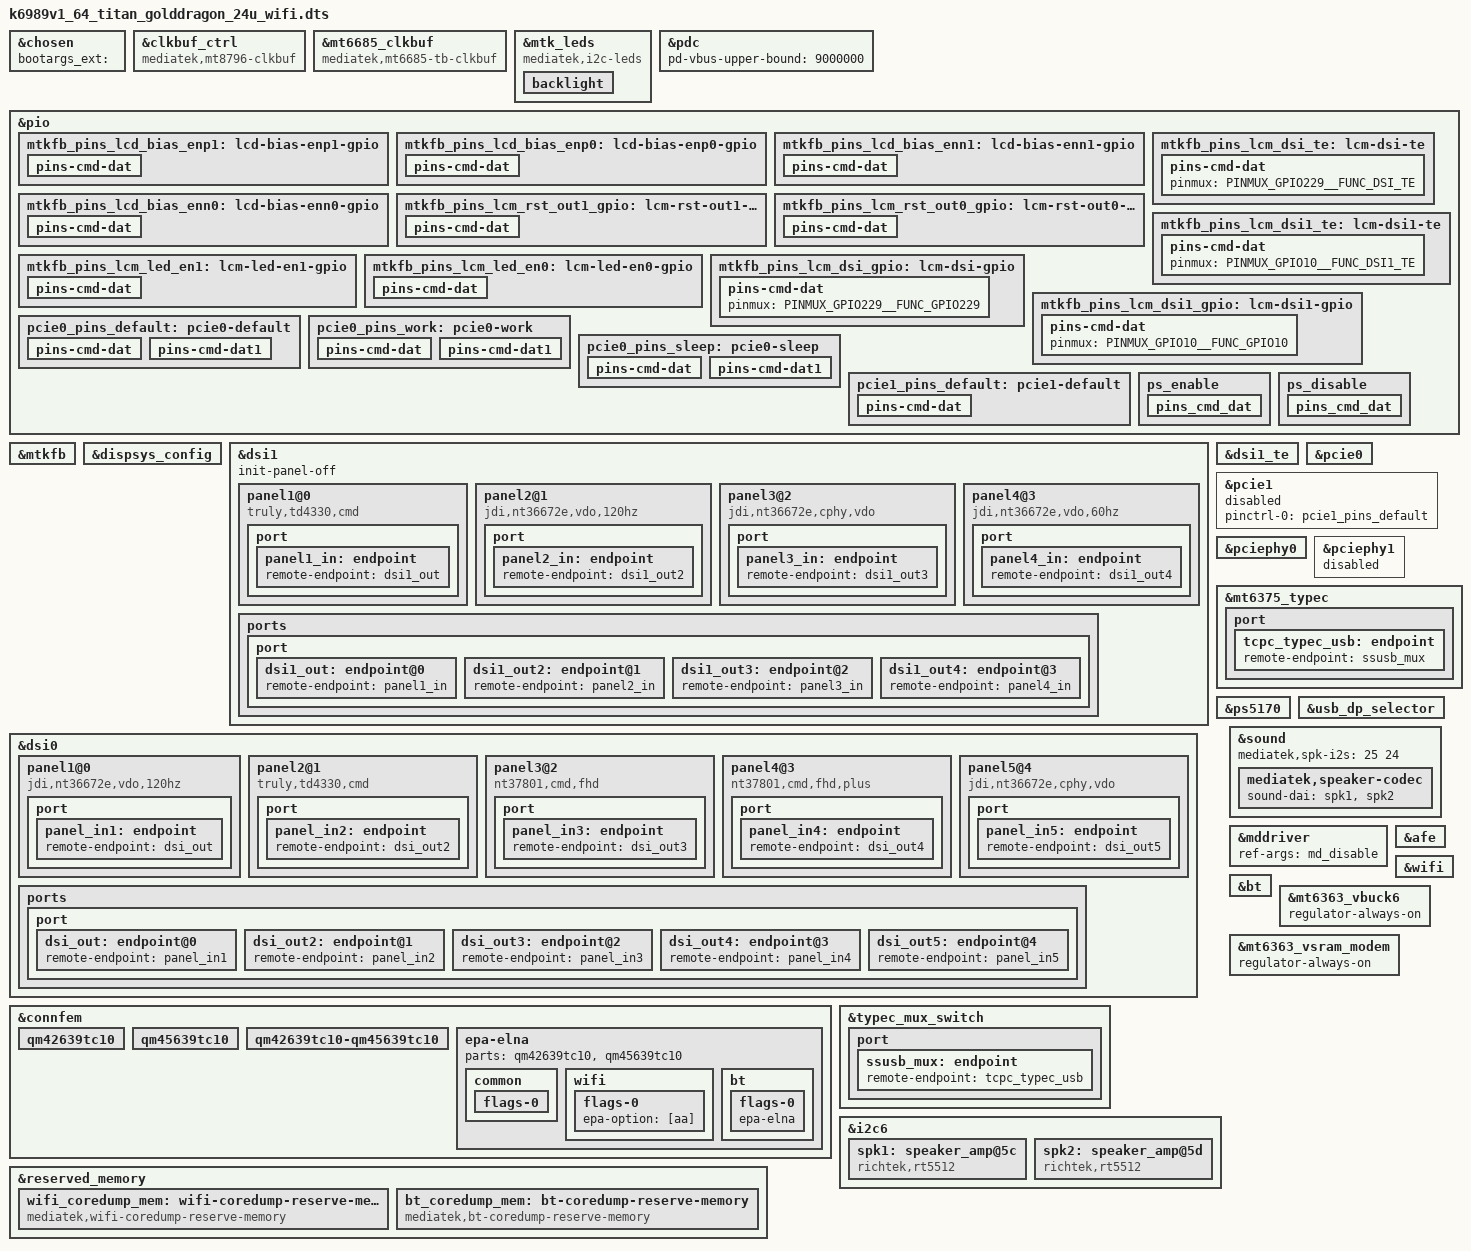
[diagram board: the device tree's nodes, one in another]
// SPDX-License-Identifier: (GPL-2.0 OR MIT)
/*
 * Copyright (C) 2022 MediaTek Inc.
 */
/dts-v1/;
/plugin/;
#include <dt-bindings/interrupt-controller/arm-gic.h>
#include <dt-bindings/interrupt-controller/irq.h>
#include <dt-bindings/pinctrl/mt6989-pinfunc.h>
#include <dt-bindings/phy/phy.h>

&chosen {
bootargs_ext = "";
};

&clkbuf_ctrl {
	compatible = "mediatek,mt8796-clkbuf";
};

&mt6685_clkbuf {
	compatible = "mediatek,mt6685-tb-clkbuf";
};

&mtk_leds {
	compatible = "mediatek,i2c-leds";

	backlight {
		led-mode = <6>;
		gate-enable = <1>;
		pwm-config = <0 1 0 0 0>;
	};
};

&pdc {
	pd-vbus-upper-bound = <9000000>;
};

&pio {
	mtkfb_pins_lcd_bias_enp1: lcd-bias-enp1-gpio {
		pins-cmd-dat {
			pinmux = <PINMUX_GPIO222__FUNC_GPIO222>;
			slew-rate = <1>;
			output-high;
		};
	};

	mtkfb_pins_lcd_bias_enp0: lcd-bias-enp0-gpio {
		pins-cmd-dat {
			pinmux = <PINMUX_GPIO222__FUNC_GPIO222>;
			slew-rate = <1>;
			output-low;
		};
	};

	mtkfb_pins_lcd_bias_enn1: lcd-bias-enn1-gpio {
		pins-cmd-dat {
			pinmux = <PINMUX_GPIO222__FUNC_GPIO222>;
			slew-rate = <1>;
			output-high;
		};
	};

	mtkfb_pins_lcd_bias_enn0: lcd-bias-enn0-gpio {
		pins-cmd-dat {
			pinmux = <PINMUX_GPIO222__FUNC_GPIO222>;
			slew-rate = <1>;
			output-low;
		};
	};

	mtkfb_pins_lcm_rst_out1_gpio: lcm-rst-out1-gpio {
		pins-cmd-dat {
			pinmux = <PINMUX_GPIO9__FUNC_GPIO9>;
			slew-rate = <1>;
			output-high;
		};
	};

	mtkfb_pins_lcm_rst_out0_gpio: lcm-rst-out0-gpio {
		pins-cmd-dat {
			pinmux = <PINMUX_GPIO230__FUNC_GPIO230>;
			slew-rate = <1>;
			output-low;
		};
	};

	mtkfb_pins_lcm_dsi_te: lcm-dsi-te {
		pins-cmd-dat {
			pinmux = <PINMUX_GPIO229__FUNC_DSI_TE>;
		};
	};

	mtkfb_pins_lcm_led_en1: lcm-led-en1-gpio {
		pins-cmd-dat {
			pinmux = <PINMUX_GPIO215__FUNC_GPIO215>;
			slew-rate = <1>;
			output-high;
		};
	};

	mtkfb_pins_lcm_led_en0: lcm-led-en0-gpio {
		pins-cmd-dat {
			pinmux = <PINMUX_GPIO215__FUNC_GPIO215>;
			slew-rate = <1>;
			output-low;
		};
	};

	mtkfb_pins_lcm_dsi1_te: lcm-dsi1-te {
		pins-cmd-dat {
			pinmux = <PINMUX_GPIO10__FUNC_DSI1_TE>;
		};
	};

	mtkfb_pins_lcm_dsi_gpio: lcm-dsi-gpio {
		pins-cmd-dat {
			pinmux = <PINMUX_GPIO229__FUNC_GPIO229>;
		};
	};

	mtkfb_pins_lcm_dsi1_gpio: lcm-dsi1-gpio {
		pins-cmd-dat {
			pinmux = <PINMUX_GPIO10__FUNC_GPIO10>;
		};
	};
};

&mtkfb {
	pinctrl-names = "lcd_bias_enp1_gpio", "lcd_bias_enp0_gpio",
		"lcd_bias_enn1_gpio", "lcd_bias_enn0_gpio",
		"lcm_rst_out1_gpio", "lcm_rst_out0_gpio",
		"mode_te_te", "lcm_led_en1_gpio", "lcm_led_en0_gpio",
		"mode_te_te1";
	pinctrl-0 = <&mtkfb_pins_lcd_bias_enp1>;
	pinctrl-1 = <&mtkfb_pins_lcd_bias_enp0>;
	pinctrl-2 = <&mtkfb_pins_lcd_bias_enn1>;
	pinctrl-3 = <&mtkfb_pins_lcd_bias_enn0>;
	pinctrl-4 = <&mtkfb_pins_lcm_rst_out1_gpio>;
	pinctrl-5 = <&mtkfb_pins_lcm_rst_out0_gpio>;
	pinctrl-6 = <&mtkfb_pins_lcm_dsi_te>;
	pinctrl-7 = <&mtkfb_pins_lcm_led_en1>;
	pinctrl-8 = <&mtkfb_pins_lcm_led_en0>;
	pinctrl-9 = <&mtkfb_pins_lcm_dsi1_te>;

	status = "okay";
};

&dispsys_config {
	pinctrl-names = "mode_te_te", "mode_te_te1";
	pinctrl-0 = <&mtkfb_pins_lcm_dsi_te>;
	pinctrl-1 = <&mtkfb_pins_lcm_dsi1_te>;
	status = "okay";
};

&dsi1 {
//	status = "okay";
	#address-cells = <1>;
	#size-cells = <0>;
	init-panel-off;
	panel1@0 {
		compatible = "truly,td4330,cmd";
		reg = <0>;
		pm-enable-gpios = <&pio 215 0>;
		reset-gpios = <&pio 9 0>;
		swap-from-dts;
		lane-swap-setting = <1 2 0 3 4 2>;
		pn-swap-setting = <1 1 1 1 1 1>;
		gate-ic = <4831>;
		pinctrl-names = "default";
		port {
			panel1_in: endpoint {
				remote-endpoint = <&dsi1_out>;
			};
		};
	};
	panel2@1 {
		compatible = "jdi,nt36672e,vdo,120hz";
		reg = <1>;
		pm-enable-gpios = <&pio 215 0>;
		reset-gpios = <&pio 9 0>;
		swap-from-dts;
		gate-ic = <4831>;
		pinctrl-names = "default";
		port {
			panel2_in: endpoint {
				remote-endpoint = <&dsi1_out2>;
			};
		};
	};
	panel3@2 {
		compatible = "jdi,nt36672e,cphy,vdo";
		reg = <2>;
		pm-enable-gpios = <&pio 215 0>;
		reset-gpios = <&pio 9 0>;
		gate-ic = <4831>;
		pinctrl-names = "default";
		port {
			panel3_in: endpoint {
				remote-endpoint = <&dsi1_out3>;
			};
		};
	};
	panel4@3 {
		compatible = "jdi,nt36672e,vdo,60hz";
		reg = <3>;
		pm-enable-gpios = <&pio 215 0>;
		reset-gpios = <&pio 9 0>;
		gate-ic = <4831>;
		pinctrl-names = "default";
		port {
			panel4_in: endpoint {
				remote-endpoint = <&dsi1_out4>;
			};
		};
	};
	ports {
		port {
			dsi1_out: endpoint@0 {
				remote-endpoint = <&panel1_in>;
			};

			dsi1_out2: endpoint@1 {
				remote-endpoint = <&panel2_in>;
			};

			dsi1_out3: endpoint@2 {
				remote-endpoint = <&panel3_in>;
			};

			dsi1_out4: endpoint@3 {
				remote-endpoint = <&panel4_in>;
			};
		};
	};
};

&dsi1_te {
	interrupt-parent = <&pio>;
	interrupts = <10 1 10 1>;
	status = "okay";
};

&dsi0 {
	status = "okay";
	#address-cells = <1>;
	#size-cells = <0>;
	panel1@0 {
		compatible = "jdi,nt36672e,vdo,120hz";
		reg = <0>;
		pm-enable-gpios = <&pio 215 0>;
		reset-gpios = <&pio 230 0>;
		gate-ic = <4831>;
		pinctrl-names = "default";
		port {
			panel_in1: endpoint {
				remote-endpoint = <&dsi_out>;
			};
		};
	};
	panel2@1 {
		compatible = "truly,td4330,cmd";
		reg = <1>;
		pm-enable-gpios = <&pio 215 0>;
		reset-gpios = <&pio 230 0>;
		gate-ic = <4831>;
		pinctrl-names = "default";
		port {
			panel_in2: endpoint {
				remote-endpoint = <&dsi_out2>;
			};
		};
	};
	panel3@2 {
		compatible = "nt37801,cmd,fhd";
		reg = <2>;
		pm-enable-gpios = <&pio 215 0>;
		reset-gpios = <&pio 230 0>;
		gate-ic = <4831>;
		pinctrl-names = "default";
		port {
			panel_in3: endpoint {
				remote-endpoint = <&dsi_out3>;
			};
		};
	};
	panel4@3 {
		compatible = "nt37801,cmd,fhd,plus";
		reg = <3>;
		pm-enable-gpios = <&pio 215 0>;
		reset-gpios = <&pio 230 0>;
		gate-ic = <4831>;
		pinctrl-names = "default";
		port {
			panel_in4: endpoint {
				remote-endpoint = <&dsi_out4>;
			};
		};
	};
	panel5@4 {
		compatible = "jdi,nt36672e,cphy,vdo";
		reg = <4>;
		pm-enable-gpios = <&pio 215 0>;
		reset-gpios = <&pio 230 0>;
		gate-ic = <4831>;
		pinctrl-names = "default";
		port {
			panel_in5: endpoint {
				remote-endpoint = <&dsi_out5>;
			};
		};
	};

	ports {
		port {
			dsi_out: endpoint@0 {
				remote-endpoint = <&panel_in1>;
			};

			dsi_out2: endpoint@1 {
				remote-endpoint = <&panel_in2>;
			};

			dsi_out3: endpoint@2 {
				remote-endpoint = <&panel_in3>;
			};

			dsi_out4: endpoint@3 {
				remote-endpoint = <&panel_in4>;
			};

			dsi_out5: endpoint@4 {
				remote-endpoint = <&panel_in5>;
			};
		};
	};
};

#if 0
&mtk_leds {
	compatible = "mediatek,i2c-leds";

	backlight {
		led_mode = <6>;
		gate_enable = <1>;
		pwm_config = <0 1 0 0 0>;
	};
};
#endif
&connfem {
	qm42639tc10: qm42639tc10 {
		vid = <3>;
		pid = <3>;
	};

	qm45639tc10: qm45639tc10 {
		vid = <3>;
		pid = <4>;
	};

	qm42639tc10-qm45639tc10 {
		mapping = <0x0 0x3 0>,	/* ANTSEL 0x00 <-> PIN #0x3: 2G WF0 PAEN */
			<0x01 0x02 0>,	/* ANTSEL 0x01 <-> PIN #0x2: 2G WF0 LNAEN */
			<0x02 0x04 0>,	/* ANTSEL 0x02 <-> PIN #0x4: 2G WF0 BTEN */
			<0x03 0x0e 0>,	/* ANTSEL 0x03 <-> PIN #0xE: 2G WF0 SEL4 */
			<0x04 0x83 0>,	/* ANTSEL 0x04 <-> PIN #0x3: 2G WF1 PAEN */
			<0x05 0x82 0>,	/* ANTSEL 0x05 <-> PIN #0x2: 2G WF1 LNAEN */
			<0x06 0x84 0>,	/* ANTSEL 0x06 <-> PIN #0x4: 2G WF1 BTEN */
			<0x07 0x8e 0>,	/* ANTSEL 0x07 <-> PIN #0xE: 2G WF1 SEL4 */
			<0x12 0x4a 0>,	/* ANTSEL 0x12 <-> PIN #0xA: 5G WF0 PAEN */
			<0x0c 0x4b 0>,	/* ANTSEL 0x0C <-> PIN #0xB: 5G WF0 LNAEN */
			<0x14 0x4c 0>,	/* ANTSEL 0x14 <-> PIN #0xC: 5G WF0 SEL3 */
			<0x0d 0x41 0>,	/* ANTSEL 0x0D <-> PIN #0x1: 5G WF0 SEL4 */
			<0x0e 0xca 0>,	/* ANTSEL 0x0E <-> PIN #0xA: 5G WF1 PAEN */
			<0x0f 0xcb 0>,	/* ANTSEL 0x0F <-> PIN #0xB: 5G WF1 LNAEN */
			<0x10 0xcc 0>,	/* ANTSEL 0x10 <-> PIN #0xC: 5G WF1 SEL3 */
			<0x11 0xc1 0>,	/* ANTSEL 0x11 <-> PIN #0x1: 5G WF1 SEL4 */
			<0x08 0x05 0>,	/* ANTSEL 0x08 <-> SPDT1 */
			<0x09 0x46 1>;	/* ANTSEL 0x09 <-> SPDT2 */
	};

	epa-elna {
		parts = <&qm42639tc10 &qm45639tc10>;

		common {
			flags-0 {
				rx-mode = [35];
				fe-ant-cnt = [81];
				fe-main-bt-share-lp2g = [80];
				fe-conn-spdt = [83];
				fe-reserved = [80];
			};
		};

		wifi {
			flags-0 {
				epa-option = [aa];
				/* open-loop; */
			};
		};

		bt {
			flags-0 {
				/* choose one of: epa-elna/epa/elna/bypass */
				epa-elna;
			};
		};
	};
};
#if 0
/* GPS GPIO standardization start */
&pio {
	gps_pins_default: gps_default {
	};
	gps_l1_lna_pins_ol: gps-l1-lna0 {
		pins-cmd-dat {
			pinmux = <PINMUX_GPIO12__FUNC_GPIO12>;
			output-low;
		};
	};
	gps_l1_lna_pins_dsp_ctrl: gps-l1-lna1 {
		pins-cmd-dat {
			pinmux = <PINMUX_GPIO12__FUNC_GPS_L1_ELNA_EN>;
		};
	};
	gps_l1_lna_pins_oh: gps-l1-lna2 {
		pins-cmd-dat {
			pinmux = <PINMUX_GPIO12__FUNC_GPIO12>;
			output-high;
		};
	};
	gps_l5_lna_pins_ol: gps-l5-lna0 {
		pins-cmd-dat {
			pinmux = <PINMUX_GPIO13__FUNC_GPIO13>;
			output-low;
		};
	};
	gps_l5_lna_pins_dsp_ctrl: gps-l5-lna1 {
		pins-cmd-dat {
			pinmux = <PINMUX_GPIO13__FUNC_GPS_L5_ELNA_EN>;
		};
	};
	gps_l5_lna_pins_oh: gps-l5-lna2 {
		pins-cmd-dat {
			pinmux = <PINMUX_GPIO13__FUNC_GPIO13>;
			output-high;
		};
	};
};
&gps {
	pinctrl-names = "default",
		"gps_l1_lna_disable",
		"gps_l1_lna_dsp_ctrl",
		"gps_l1_lna_enable",
		"gps_l5_lna_disable",
		"gps_l5_lna_dsp_ctrl",
		"gps_l5_lna_enable";
	pinctrl-0 = <&gps_pins_default>;
	pinctrl-1 = <&gps_l1_lna_pins_ol>;
	pinctrl-2 = <&gps_l1_lna_pins_dsp_ctrl>;
	pinctrl-3 = <&gps_l1_lna_pins_oh>;
	pinctrl-4 = <&gps_l5_lna_pins_ol>;
	pinctrl-5 = <&gps_l5_lna_pins_dsp_ctrl>;
	pinctrl-6 = <&gps_l5_lna_pins_oh>;
	status = "okay";
};
/* GPS GPIO standardization end */
#endif

&pcie0 {
	pinctrl-names = "default", "sleep", "work";
	pinctrl-0 = <&pcie0_pins_default>;
	pinctrl-1 = <&pcie0_pins_sleep>;
	pinctrl-2 = <&pcie0_pins_work>;
	max-link-speed = <3>;
	status = "okay";
};

&pcie1 {
	pinctrl-names = "default";
	pinctrl-0 = <&pcie1_pins_default>;
	status = "disabled";
};

&pciephy0 {
	status = "okay";
};

&pciephy1 {
	status = "disabled";
};

/* PCIe pinmux start */
&pio {
	pcie0_pins_default: pcie0-default {
		pins-cmd-dat {
			pinmux = <PINMUX_GPIO143__FUNC_GPIO143>;
			output-low;
		};

		pins-cmd-dat1 {
			pinmux = <PINMUX_GPIO144__FUNC_GPIO144>,
				 <PINMUX_GPIO145__FUNC_GPIO145>;
			bias-pull-up;
			input-enable;
		};
	};

	pcie0_pins_work: pcie0-work {
		pins-cmd-dat {
			pinmux = <PINMUX_GPIO143__FUNC_PCIE_PERSTN>,
				 <PINMUX_GPIO145__FUNC_PCIE_CLKREQN>;
			bias-pull-up;
		};

		pins-cmd-dat1 {
			pinmux = <PINMUX_GPIO144__FUNC_GPIO144>;
			bias-pull-down;
			input-enable;
		};
	};

	pcie0_pins_sleep: pcie0-sleep {
		pins-cmd-dat {
			pinmux = <PINMUX_GPIO143__FUNC_GPIO143>;
			output-low;
		};

		pins-cmd-dat1 {
			pinmux = <PINMUX_GPIO144__FUNC_GPIO144>,
				 <PINMUX_GPIO145__FUNC_GPIO145>;
			bias-pull-up;
			input-enable;
		};
	};

	pcie1_pins_default: pcie1-default {
		pins-cmd-dat {
			pinmux = <PINMUX_GPIO2__FUNC_PCIE_CLKREQN_P1>,
				 <PINMUX_GPIO3__FUNC_PCIE_WAKEN_P1>,
				 <PINMUX_GPIO4__FUNC_PCIE_PERSTN_P1>;
			bias-pull-up;
		};
	};
};
/* PCIe pinmux end */

/* usb typec mux start */
&pio {

	ps_enable: ps_enable {
		pins_cmd_dat {
			pinmux = <PINMUX_GPIO111__FUNC_GPIO111>;
			output-high;
		};
	};

	ps_disable: ps_disable {
		pins_cmd_dat {
			pinmux = <PINMUX_GPIO111__FUNC_GPIO111>;
			output-low;
		};
	};

};

&mt6375_typec {
	port {
		tcpc_typec_usb: endpoint {
			remote-endpoint = <&ssusb_mux>;
		};
	};
};

&typec_mux_switch {
	orientation-switch;
	mode-switch;
	accessory;
	port {
		ssusb_mux: endpoint {
			remote-endpoint = <&tcpc_typec_usb>;
		};
	};
};

&ps5170 {
	pinctrl-names = "enable", "disable";
	pinctrl-0 = <&ps_enable>;
	pinctrl-1 = <&ps_disable>;
	status = "okay";
};

&usb_dp_selector {
	status = "okay";
};
/* usb typec mux end */

#if 0
&pdc {
	pd_vbus_upper_bound = <12000000>;
};
#endif

&i2c6 {
	spk1: speaker_amp@5c {
		compatible = "richtek,rt5512";
		#sound-dai-cells = <0>;
		reg = <0x5c>;
		status = "okay";
		sound-name-prefix = "Left";
	};

	spk2: speaker_amp@5d {
		compatible = "richtek,rt5512";
		#sound-dai-cells = <0>;
		reg = <0x5d>;
		status = "okay";
		sound-name-prefix = "Right";
	};
};

&sound {
	mediatek,spk-i2s = <25 24>;
	mediatek,speaker-codec {
		sound-dai = <&spk1>, <&spk2>;
	};
};

&mddriver {
	ref-args = "md_disable";
};

&afe {
	etdm-out-ch = <4>;
	etdm-in-ch = <4>;
	mediatek,ap-dmic = <1>;
};

&wifi {
	flavor-bin = "dx3";
	default-memdump = "2";
};

&bt {
	flavor-bin = "dx3";
};

&mt6363_vbuck6 {
	regulator-always-on;
};

&mt6363_vsram_modem {
	regulator-always-on;
};

&reserved_memory {
	wifi_coredump_mem: wifi-coredump-reserve-memory {
		compatible = "mediatek,wifi-coredump-reserve-memory";
		no-map;
		size = <0 0x500000>;
		alignment = <0 0x1000000>;
		alloc-ranges = <0 0x40000000 0 0x80000000>;
	};
};

&reserved_memory {
	bt_coredump_mem: bt-coredump-reserve-memory {
		compatible = "mediatek,bt-coredump-reserve-memory";
		no-map;
		size = <0 0x500000>;
		alignment = <0 0x1000000>;
		alloc-ranges = <0 0x40000000 0 0x80000000>;
	};
};

&bt {
	memory-region = <&bt_coredump_mem>;
};

#include <k6989v1_64_titan_golddragon_24u_wifi/cust.dtsi>
#include "mediatek/cust_mt6989_touch_1080x2400_mult.dtsi"
#include "mediatek/cust_mt6989_camera_v4l2.dtsi"
/*End of this file, DO NOT ADD ANYTHING HERE*/
